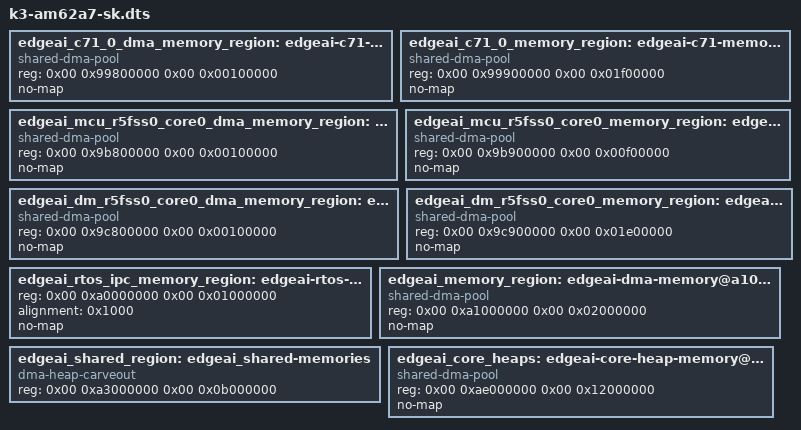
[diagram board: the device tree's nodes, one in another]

 
 /* 
  * IMPORTANT NOTE: Follow below instructions to apply the updated memory map to linux dtsi file, 
  * 
  * 1. Copy the memory sections, from the generated dts file, to the file shown below under reserved_memory: reserved-memory { ... } 
  *     ${LINUX_KERNEL_PATH}/arch/arm64/boot/dts/ti/k3-am62a7-sk.dts
  * 
  * 2. Rebuild the dtb, dtbo from PSDK Linux install directory 
  *      make linux-dtbs 
  * 
  * 3. Install the dtb, dtbo to the rootfs/boot folder on SD card 
  *      sudo make linux-dtbs_intall; sync 
  * 
   */


	edgeai_c71_0_dma_memory_region: edgeai-c71-dma-memory@99800000 {
		compatible = "shared-dma-pool";
		reg = <0x00 0x99800000 0x00 0x00100000>;
		no-map;
	};
	edgeai_c71_0_memory_region: edgeai-c71-memory@99900000 {
		compatible = "shared-dma-pool";
		reg = <0x00 0x99900000 0x00 0x01f00000>;
		no-map;
	};
	edgeai_mcu_r5fss0_core0_dma_memory_region: edgeai-dm-r5f-dma-memory@9b800000 {
		compatible = "shared-dma-pool";
		reg = <0x00 0x9b800000 0x00 0x00100000>;
		no-map;
	};
	edgeai_mcu_r5fss0_core0_memory_region: edgeai-r5f-memory@9b900000 {
		compatible = "shared-dma-pool";
		reg = <0x00 0x9b900000 0x00 0x00f00000>;
		no-map;
	};
	edgeai_dm_r5fss0_core0_dma_memory_region: edgeai-dm-r5f-dma-memory@9c800000 {
		compatible = "shared-dma-pool";
		reg = <0x00 0x9c800000 0x00 0x00100000>;
		no-map;
	};
	edgeai_dm_r5fss0_core0_memory_region: edgeai-r5f-memory@9c900000 {
		compatible = "shared-dma-pool";
		reg = <0x00 0x9c900000 0x00 0x01e00000>;
		no-map;
	};
	edgeai_rtos_ipc_memory_region: edgeai-rtos-ipc-memory-region {
		reg = <0x00 0xa0000000 0x00 0x01000000>;
		alignment = <0x1000>;
		no-map;
	};
	edgeai_memory_region: edgeai-dma-memory@a1000000 {
		compatible = "shared-dma-pool";
		reg = <0x00 0xa1000000 0x00 0x02000000>;
		no-map;
	};
	edgeai_shared_region: edgeai_shared-memories {
		compatible = "dma-heap-carveout";
		reg = <0x00 0xa3000000 0x00 0x0b000000>;
	};
	edgeai_core_heaps: edgeai-core-heap-memory@ae000000 {
		compatible = "shared-dma-pool";
		reg = <0x00 0xae000000 0x00 0x12000000>;
		no-map;
	};

